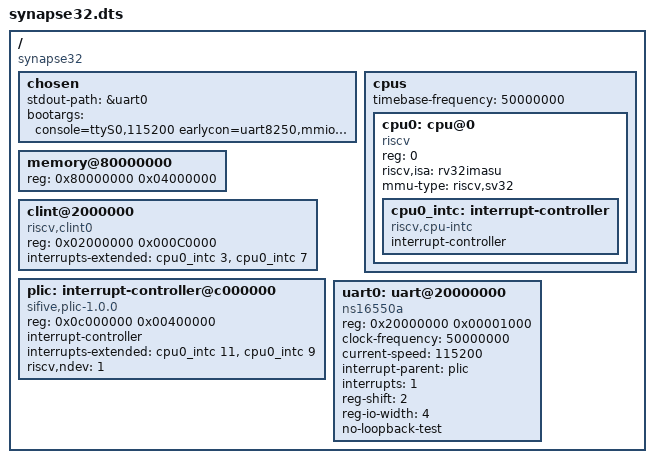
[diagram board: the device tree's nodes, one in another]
/dts-v1/;

/ {
	#address-cells = <1>;
	#size-cells = <1>;
	compatible = "synapse32";

	chosen {
		stdout-path = &uart0;
		bootargs = "console=ttyS0,115200 earlycon=uart8250,mmio32,0x20000000 loglevel=8 rdinit=/init cpuidle.off=1";
	};

	cpus {
		#address-cells = <1>;
		#size-cells = <0>;
		timebase-frequency = <50000000>;

		cpu0: cpu@0 {
			compatible = "riscv";
			device_type = "cpu";
			reg = <0>;
			riscv,isa = "rv32imasu";
			mmu-type = "riscv,sv32";
			status = "okay";

			cpu0_intc: interrupt-controller {
				compatible = "riscv,cpu-intc";
				interrupt-controller;
				#interrupt-cells = <1>;
			};
		};
	};

	/*
	 * 64MB unified RAM, matching INSTR_MEM_SIZE in
	 * rtl/include/memory_map.vh: OpenSBI at the base, kernel at +2MB
	 * (FW_JUMP_ADDR = 0x80200000 in build_opensbi.sh).
	 */
	memory@80000000 {
		device_type = "memory";
		reg = <0x80000000 0x04000000>;
	};

	/*
	 * CLINT: mtimecmp at 0x02004000, mtime at 0x0200BFF8.
	 * riscv,clint0 covers the full region starting at 0x02000000.
	 * MSIP (IPI) registers at 0x02000000 are not implemented —
	 * safe for single-hart because openSBI never actually fires IPIs.
	 */
	clint@2000000 {
		compatible = "riscv,clint0";
		reg = <0x02000000 0x000C0000>;
		interrupts-extended = <&cpu0_intc 3 &cpu0_intc 7>;
	};

	plic: interrupt-controller@c000000 {
		compatible = "sifive,plic-1.0.0";
		reg = <0x0c000000 0x00400000>;
		#address-cells = <0>;
		interrupt-controller;
		#interrupt-cells = <1>;
		interrupts-extended = <&cpu0_intc 11 &cpu0_intc 9>;
		riscv,ndev = <1>;
	};

	uart0: uart@20000000 {
		compatible = "ns16550a";
		reg = <0x20000000 0x00001000>;
		clock-frequency = <50000000>;
		current-speed = <115200>;
		interrupt-parent = <&plic>;
		interrupts = <1>;
		reg-shift = <2>;
		reg-io-width = <4>;
		no-loopback-test;
	};
};
